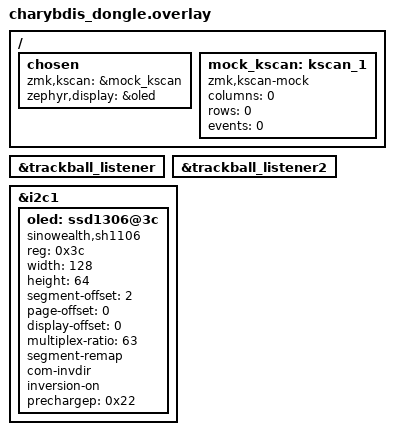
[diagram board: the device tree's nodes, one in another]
#include "charybdis.dtsi"
#include "split_input_common.dtsi"

/ {
    chosen {
        zmk,kscan = &mock_kscan;
        zephyr,display = &oled;
    };

    mock_kscan: kscan_1 {
        compatible = "zmk,kscan-mock";
        columns = <0>;
        rows = <0>;
        events = <0>;
    };
};

&trackball_listener {
    status = "okay";
};
&trackball_listener2 {
    status = "okay";
};

/* 【変更】&i2c0 → &i2c1
   理由: Zephyr 4.1の新xiao_bleボード定義では、XIAO標準のSDA/SCLピン(D4/D5)が
   i2c1としてpinctrl設定済みで定義される(旧定義ではi2c0だった)。
   i2c0はpinctrl未設定の裸ノードのため、有効化すると
   「pinctrl-0 is required」エラーになる。物理配線は同じなので接続変更は不要 */
&i2c1 {
    status = "okay";
    
    oled: ssd1306@3c {
        compatible = "sinowealth,sh1106";
        reg = <0x3c>;
        width = <128>;
        height = <64>;
        segment-offset = <2>;
        page-offset = <0>;
        display-offset = <0>;
        multiplex-ratio = <63>;
        segment-remap;
        com-invdir;
        inversion-on;
        prechargep = <0x22>;
    };
};
